VERSION ""

NS_ :

BS_:

BU_: MS6_Logger_CAN_Bus_1 GCM IZZE_RL IZZE_FL IZZE_RR IZZE_FR IMU SG_RIGHT SG_LEFT BRK_IR ABS PDM Wheel S350

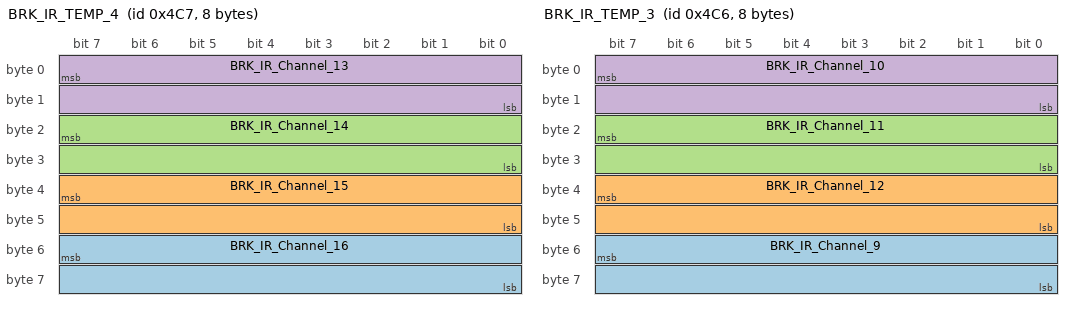
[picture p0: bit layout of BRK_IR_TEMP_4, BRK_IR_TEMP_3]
BO_ 1223 BRK_IR_TEMP_4: 8 Vector__XXX
 SG_ BRK_IR_Channel_16 : 55|16@0+ (0.1,-100) [0|65535] "C" Vector__XXX
 SG_ BRK_IR_Channel_15 : 39|16@0+ (0.1,-100) [0|65535] "C" Vector__XXX
 SG_ BRK_IR_Channel_14 : 23|16@0+ (0.1,-100) [0|65535] "C" Vector__XXX
 SG_ BRK_IR_Channel_13 : 7|16@0+ (0.1,-100) [0|65535] "C" Vector__XXX

BO_ 1222 BRK_IR_TEMP_3: 8 Vector__XXX
 SG_ BRK_IR_Channel_9 : 55|16@0+ (0.1,-100) [0|65535] "C" Vector__XXX
 SG_ BRK_IR_Channel_12 : 39|16@0+ (0.1,-100) [0|65535] "C" Vector__XXX
 SG_ BRK_IR_Channel_11 : 23|16@0+ (0.1,-100) [0|65535] "C" Vector__XXX
 SG_ BRK_IR_Channel_10 : 7|16@0+ (0.1,-100) [0|65535] "C" Vector__XXX

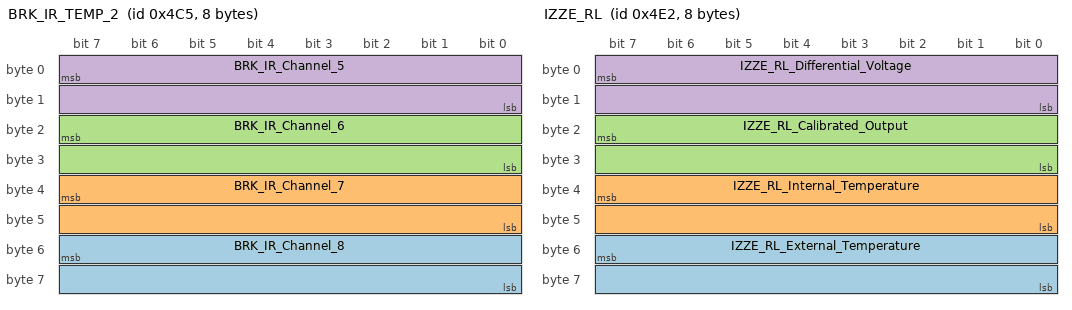
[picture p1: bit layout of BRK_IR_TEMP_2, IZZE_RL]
BO_ 1221 BRK_IR_TEMP_2: 8 Vector__XXX
 SG_ BRK_IR_Channel_8 : 55|16@0+ (0.1,-100) [0|65535] "C" Vector__XXX
 SG_ BRK_IR_Channel_7 : 39|16@0+ (0.1,-100) [0|65535] "C" Vector__XXX
 SG_ BRK_IR_Channel_6 : 23|16@0+ (0.1,-100) [0|65535] "C" Vector__XXX
 SG_ BRK_IR_Channel_5 : 7|16@0+ (0.1,-100) [0|65535] "C" Vector__XXX

BO_ 1552 GCM_Bosch: 8 GCM
 SG_ GCM_Upshift_Bosch : 1|1@1+ (1,0) [0|0] "" Vector__XXX
 SG_ GCM_Downshift_Bosch : 0|1@1+ (1,0) [0|0] "" Vector__XXX

BO_ 1250 IZZE_RL: 8 IZZE_RL
 SG_ IZZE_RL_External_Temperature : 55|16@0- (0.1,0) [0|0] "C" Vector__XXX
 SG_ IZZE_RL_Internal_Temperature : 39|16@0- (0.1,0) [0|0] "C" Vector__XXX
 SG_ IZZE_RL_Calibrated_Output : 23|16@0- (0.1,0) [0|0] "F" Vector__XXX
 SG_ IZZE_RL_Differential_Voltage : 7|16@0- (1,0) [0|0] "µV" Vector__XXX

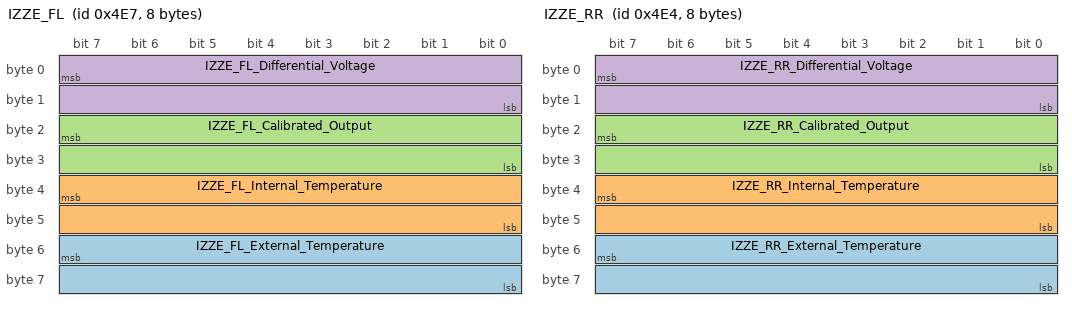
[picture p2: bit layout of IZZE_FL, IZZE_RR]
BO_ 1255 IZZE_FL: 8 IZZE_FL
 SG_ IZZE_FL_External_Temperature : 55|16@0- (0.1,0) [0|0] "C" Vector__XXX
 SG_ IZZE_FL_Internal_Temperature : 39|16@0- (0.1,0) [0|0] "C" Vector__XXX
 SG_ IZZE_FL_Calibrated_Output : 23|16@0- (0.1,0) [0|0] "F" Vector__XXX
 SG_ IZZE_FL_Differential_Voltage : 7|16@0- (1,0) [0|0] "µV" Vector__XXX

BO_ 1252 IZZE_RR: 8 IZZE_RR
 SG_ IZZE_RR_External_Temperature : 55|16@0- (0.1,0) [0|0] "C" Vector__XXX
 SG_ IZZE_RR_Internal_Temperature : 39|16@0- (0.1,0) [0|0] "C" Vector__XXX
 SG_ IZZE_RR_Calibrated_Output : 23|16@0- (0.1,0) [0|0] "F" Vector__XXX
 SG_ IZZE_RR_Differential_Voltage : 7|16@0- (1,0) [0|0] "µV" Vector__XXX

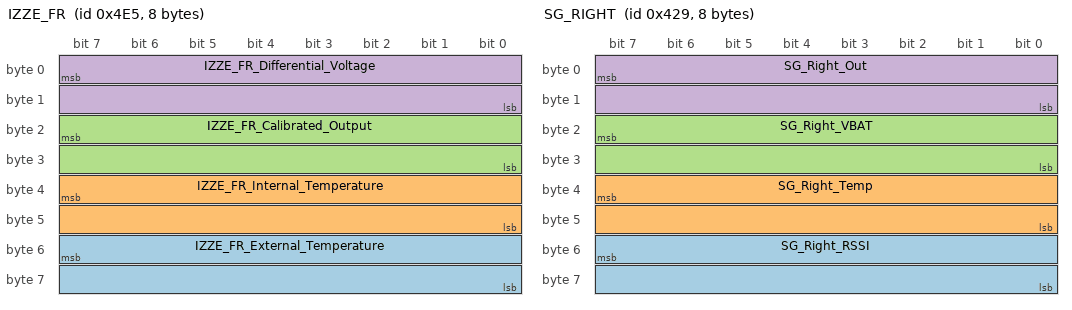
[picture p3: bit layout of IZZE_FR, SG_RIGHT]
BO_ 1253 IZZE_FR: 8 IZZE_FR
 SG_ IZZE_FR_External_Temperature : 55|16@0- (0.1,0) [0|0] "C" Vector__XXX
 SG_ IZZE_FR_Internal_Temperature : 39|16@0- (0.1,0) [0|0] "C" Vector__XXX
 SG_ IZZE_FR_Calibrated_Output : 23|16@0- (0.1,0) [0|0] "F" Vector__XXX
 SG_ IZZE_FR_Differential_Voltage : 7|16@0- (1,0) [0|0] "µV" Vector__XXX

BO_ 380 IMU2: 8 IMU
 SG_ IMU_Z_Accel : 32|16@1+ (0.0001274,-4.1746432) [0|0] "g" Vector__XXX

BO_ 1065 SG_RIGHT: 8 SG_RIGHT
 SG_ SG_Right_RSSI : 55|16@0- (1,0) [0|0] "dBm" Vector__XXX
 SG_ SG_Right_Temp : 39|16@0- (0.1,0) [0|0] "C" Vector__XXX
 SG_ SG_Right_VBAT : 23|16@0- (0.001,0) [0|0] "V" Vector__XXX
 SG_ SG_Right_Out : 7|16@0- (-1,0) [0|0] "uV" Vector__XXX

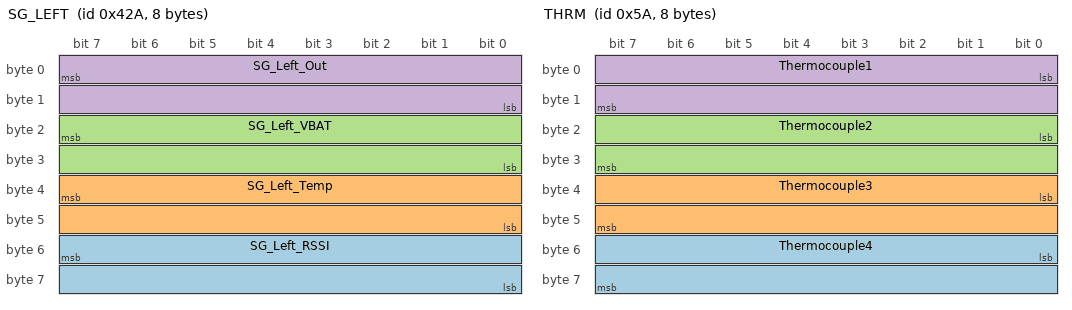
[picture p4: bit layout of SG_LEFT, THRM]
BO_ 1066 SG_LEFT: 8 SG_LEFT
 SG_ SG_Left_RSSI : 55|16@0- (1,0) [0|0] "dBm" Vector__XXX
 SG_ SG_Left_Temp : 39|16@0- (0.1,0) [0|0] "C" Vector__XXX
 SG_ SG_Left_VBAT : 23|16@0- (0.001,0) [0|0] "V" Vector__XXX
 SG_ SG_Left_Out : 7|16@0- (1,0) [0|0] "uV" Vector__XXX

BO_ 90 THRM: 8 Vector__XXX
 SG_ Thermocouple4 : 48|16@1- (0.25,0) [-32768|32767] "C" Vector__XXX
 SG_ Thermocouple3 : 32|16@1- (0.25,0) [-32768|32767] "C" Vector__XXX
 SG_ Thermocouple2 : 16|16@1- (0.25,0) [-32768|32767] "C" Vector__XXX
 SG_ Thermocouple1 : 0|16@1- (0.25,0) [-32768|32767] "C" Vector__XXX

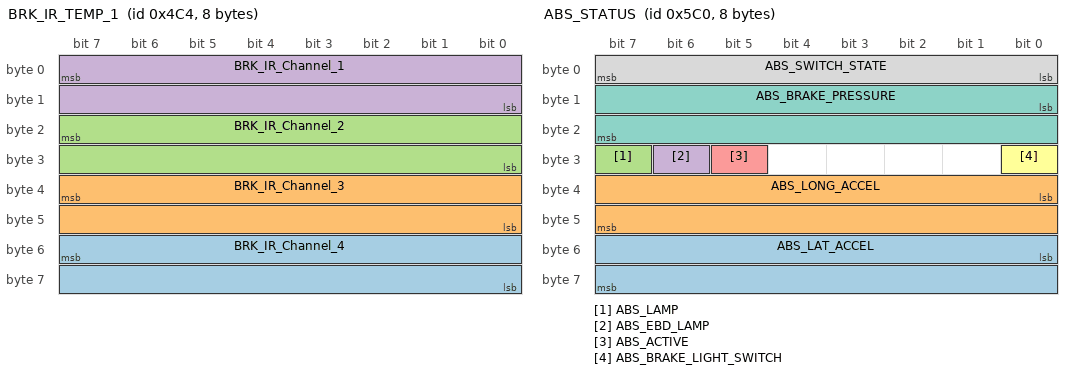
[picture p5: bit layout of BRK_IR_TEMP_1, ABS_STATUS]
BO_ 1220 BRK_IR_TEMP_1: 8 BRK_IR
 SG_ BRK_IR_Channel_4 : 55|16@0+ (0.1,-100) [0|65535] "C" Vector__XXX
 SG_ BRK_IR_Channel_3 : 39|16@0+ (0.1,-100) [0|65535] "C" Vector__XXX
 SG_ BRK_IR_Channel_2 : 23|16@0+ (0.1,-100) [0|65535] "C" Vector__XXX
 SG_ BRK_IR_Channel_1 : 7|16@0+ (0.1,-100) [0|65535] "C" Vector__XXX

BO_ 1472 ABS_STATUS: 8 ABS
 SG_ ABS_LAT_ACCEL : 48|16@1- (0.0001274,32768) [0|0] "g" Vector__XXX
 SG_ ABS_LONG_ACCEL : 32|16@1- (0.0001274,32768) [0|0] "g" Vector__XXX
 SG_ ABS_LAMP : 31|1@1+ (1,0) [0|0] "" Vector__XXX
 SG_ ABS_EBD_LAMP : 30|1@1+ (1,0) [0|0] "" Vector__XXX
 SG_ ABS_ACTIVE : 29|1@1+ (1,0) [0|0] "" Vector__XXX
 SG_ ABS_BRAKE_LIGHT_SWITCH : 24|1@1+ (1,0) [0|0] "" Vector__XXX
 SG_ ABS_BRAKE_PRESSURE : 8|16@1- (0.0153,0) [0|0] "bar" Vector__XXX
 SG_ ABS_SWITCH_STATE : 0|8@1+ (1,0) [0|0] "" Vector__XXX

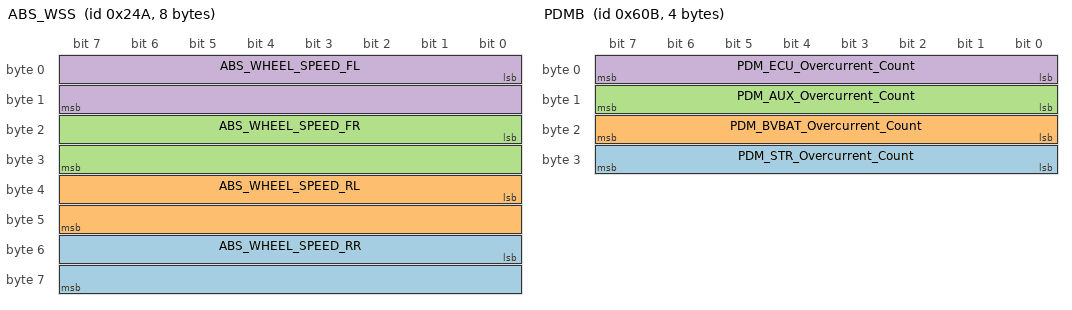
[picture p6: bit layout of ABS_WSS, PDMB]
BO_ 586 ABS_WSS: 8 ABS
 SG_ ABS_WHEEL_SPEED_RR : 48|16@1+ (0.015625,0) [0|0] "m/s" Vector__XXX
 SG_ ABS_WHEEL_SPEED_RL : 32|16@1+ (0.015625,0) [0|0] "m/s" Vector__XXX
 SG_ ABS_WHEEL_SPEED_FR : 16|16@1+ (0.015625,0) [0|0] "m/s" Vector__XXX
 SG_ ABS_WHEEL_SPEED_FL : 0|16@1+ (0.015625,0) [0|0] "m/s" Vector__XXX

BO_ 1027 BOSCH_LT2_3: 3 Vector__XXX
 SG_ LT2_Lambda_2 m0 : 8|16@1+ (0.001,0) [0|0] "L" Vector__XXX
 SG_ LT2_Row_Count M : 0|8@1+ (1,0) [0|0] "" Vector__XXX

BO_ 1122 BOSCH_LT2_2: 3 Vector__XXX
 SG_ LT2_Lambda_1 m0 : 8|16@1+ (0.001,0) [0|0] "L" Vector__XXX
 SG_ LT2_Row_Count M : 0|8@1+ (1,0) [0|0] "" Vector__XXX

BO_ 1121 BOSCH_LT2_1: 3 Vector__XXX
 SG_ LT2_Lambda_2 m0 : 8|16@1+ (0.001,0) [0|0] "L" Vector__XXX
 SG_ LT2_Row_Count M : 0|8@1+ (1,0) [0|0] "" Vector__XXX

BO_ 1120 BOSCH_LT2_0: 8 Vector__XXX
 SG_ LT2_Lambda_1 m0 : 8|16@1+ (0.001,0) [0|0] "L" Vector__XXX
 SG_ LT2_Row_Count M : 0|8@1+ (1,0) [0|0] "" Vector__XXX

BO_ 1547 PDMB: 4 PDM
 SG_ PDM_STR_Overcurrent_Count : 24|8@1+ (1,0) [0|0] "" Vector__XXX
 SG_ PDM_BVBAT_Overcurrent_Count : 16|8@1+ (1,0) [0|0] "" Vector__XXX
 SG_ PDM_AUX_Overcurrent_Count : 8|8@1+ (1,0) [0|0] "" Vector__XXX
 SG_ PDM_ECU_Overcurrent_Count : 0|8@1+ (1,0) [0|0] "" Vector__XXX

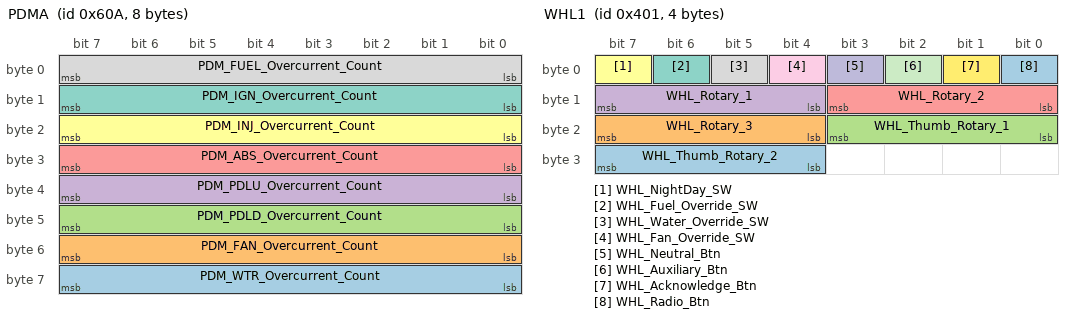
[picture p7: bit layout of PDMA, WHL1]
BO_ 1546 PDMA: 8 PDM
 SG_ PDM_WTR_Overcurrent_Count : 56|8@1+ (1,0) [0|0] "" Vector__XXX
 SG_ PDM_FAN_Overcurrent_Count : 48|8@1+ (1,0) [0|0] "" Vector__XXX
 SG_ PDM_PDLD_Overcurrent_Count : 40|8@1+ (1,0) [0|0] "" Vector__XXX
 SG_ PDM_PDLU_Overcurrent_Count : 32|8@1+ (1,0) [0|0] "" Vector__XXX
 SG_ PDM_ABS_Overcurrent_Count : 24|8@1+ (1,0) [0|0] "" Vector__XXX
 SG_ PDM_INJ_Overcurrent_Count : 16|8@1+ (1,0) [0|0] "" Vector__XXX
 SG_ PDM_IGN_Overcurrent_Count : 8|8@1+ (1,0) [0|0] "" Vector__XXX
 SG_ PDM_FUEL_Overcurrent_Count : 0|8@1+ (1,0) [0|0] "" Vector__XXX

BO_ 376 IMU1: 8 IMU
 SG_ IMU_X_Accel : 32|16@1+ (0.0001274,-4.1746432) [0|0] "g" Vector__XXX
 SG_ IMU_Roll_Rate : 0|16@1+ (0.005,-163.84) [0|0] "deg/s/s" Vector__XXX

BO_ 372 IMU0: 8 IMU
 SG_ IMU_Y_Accel : 32|16@1+ (0.0001274,-4.1746432) [0|0] "g" Vector__XXX
 SG_ IMU_Yaw_Rate : 0|16@1+ (0.005,-163.84) [0|0] "deg/s" Vector__XXX

BO_ 1025 WHL1: 4 Wheel
 SG_ WHL_Thumb_Rotary_2 : 28|4@1+ (1,0) [0|0] "" Vector__XXX
 SG_ WHL_Rotary_3 : 20|4@1+ (1,0) [0|0] "" Vector__XXX
 SG_ WHL_Thumb_Rotary_1 : 16|4@1+ (1,0) [0|0] "" Vector__XXX
 SG_ WHL_Rotary_1 : 12|4@1+ (1,0) [0|0] "" Vector__XXX
 SG_ WHL_Rotary_2 : 8|4@1+ (1,0) [0|0] "" Vector__XXX
 SG_ WHL_NightDay_SW : 7|1@1+ (1,0) [0|0] "" Vector__XXX
 SG_ WHL_Fuel_Override_SW : 6|1@1+ (1,0) [0|0] "" Vector__XXX
 SG_ WHL_Water_Override_SW : 5|1@1+ (1,0) [0|0] "" Vector__XXX
 SG_ WHL_Fan_Override_SW : 4|1@1+ (1,0) [0|0] "" Vector__XXX
 SG_ WHL_Neutral_Btn : 3|1@1+ (1,0) [0|0] "" Vector__XXX
 SG_ WHL_Auxiliary_Btn : 2|1@1+ (1,0) [0|0] "" Vector__XXX
 SG_ WHL_Acknowledge_Btn : 1|1@1+ (1,0) [0|0] "" Vector__XXX
 SG_ WHL_Radio_Btn : 0|1@1+ (1,0) [0|0] "" Vector__XXX

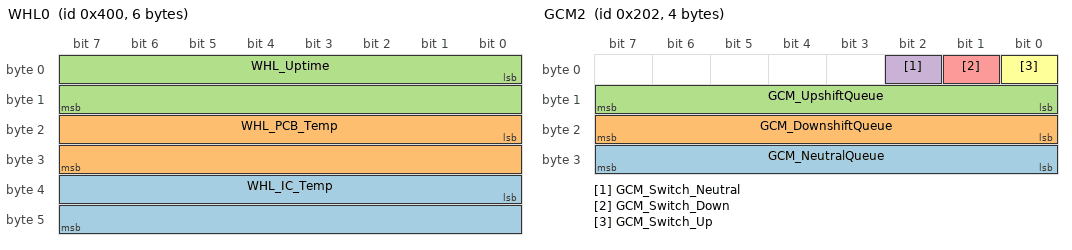
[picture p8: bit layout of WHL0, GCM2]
BO_ 1024 WHL0: 6 Wheel
 SG_ WHL_IC_Temp : 32|16@1- (0.005,0) [0|0] "C" Vector__XXX
 SG_ WHL_PCB_Temp : 16|16@1- (0.005,0) [0|0] "C" Vector__XXX
 SG_ WHL_Uptime : 0|16@1+ (1,0) [0|0] "s" Vector__XXX

BO_ 514 GCM2: 4 GCM
 SG_ GCM_NeutralQueue : 24|8@1+ (1,0) [0|0] "" Vector__XXX
 SG_ GCM_DownshiftQueue : 16|8@1+ (1,0) [0|0] "" Vector__XXX
 SG_ GCM_UpshiftQueue : 8|8@1+ (1,0) [0|0] "" Vector__XXX
 SG_ GCM_Switch_Neutral : 2|1@1+ (1,0) [0|0] "" Vector__XXX
 SG_ GCM_Switch_Down : 1|1@1+ (1,0) [0|0] "" Vector__XXX
 SG_ GCM_Switch_Up : 0|1@1+ (1,0) [0|0] "" Vector__XXX

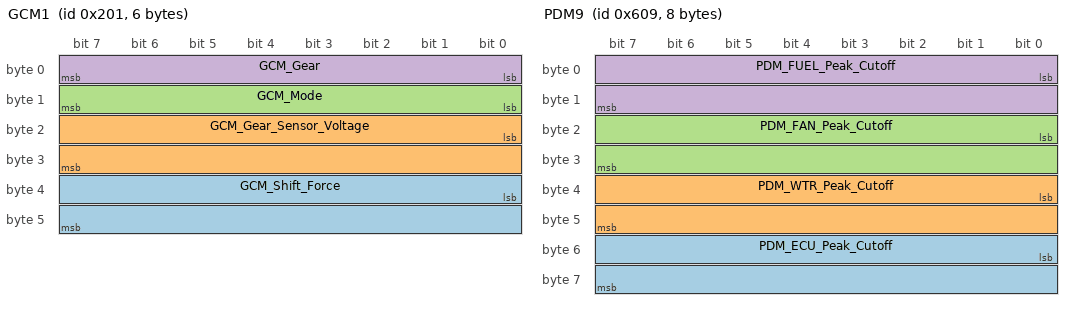
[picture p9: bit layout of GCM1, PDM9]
BO_ 513 GCM1: 6 GCM
 SG_ GCM_Shift_Force : 32|16@1- (0.01,0) [0|0] "N" Vector__XXX
 SG_ GCM_Gear_Sensor_Voltage : 16|16@1+ (0.0001,0) [0|0] "V" Vector__XXX
 SG_ GCM_Mode : 8|8@1+ (1,0) [0|0] "" Vector__XXX
 SG_ GCM_Gear : 0|8@1+ (1,0) [0|0] "" Vector__XXX

BO_ 15 ERR: 4 Vector__XXX
 SG_ ERR_Code : 16|16@1+ (1,0) [0|0] "" Vector__XXX
 SG_ ERR_Origin_Node : 0|16@1+ (1,0) [0|0] "" Vector__XXX

BO_ 1537 PDM1: 8 PDM
 SG_ PDM_FuelPrime : 63|1@1+ (1,0) [0|0] "" Vector__XXX
 SG_ PDM_OverTemp : 62|1@1+ (1,0) [0|0] "" Vector__XXX
 SG_ PDM_STR_SW : 55|1@1+ (1,0) [0|0] "" Vector__XXX
 SG_ PDM_ON_SW : 54|1@1+ (1,0) [0|0] "" Vector__XXX
 SG_ PDM_ACT_UP_SW : 53|1@1+ (1,0) [0|0] "" Vector__XXX
 SG_ PDM_ACT_DN_SW : 52|1@1+ (1,0) [0|0] "" Vector__XXX
 SG_ PDM_KILL_SW : 51|1@1+ (1,0) [0|0] "" Vector__XXX
 SG_ PDM_ABS_SW : 50|1@1+ (1,0) [0|0] "" Vector__XXX
 SG_ PDM_AUX1_SW : 49|1@1+ (1,0) [0|0] "" Vector__XXX
 SG_ PDM_AUX2_SW : 48|1@1+ (1,0) [0|0] "" Vector__XXX
 SG_ PDM_Total_Current : 32|16@1+ (0.01,0) [0|0] "A" Vector__XXX
 SG_ PDM_FUEL_Peak : 31|1@1+ (1,0) [0|0] "" Vector__XXX
 SG_ PDM_IGN_Peak : 30|1@1+ (1,0) [0|0] "" Vector__XXX
 SG_ PDM_INJ_Peak : 29|1@1+ (1,0) [0|0] "" Vector__XXX
 SG_ PDM_ABS_Peak : 28|1@1+ (1,0) [0|0] "" Vector__XXX
 SG_ PDM_PDLU_Peak : 27|1@1+ (1,0) [0|0] "" Vector__XXX
 SG_ PDM_PDLD_Peak : 26|1@1+ (1,0) [0|0] "" Vector__XXX
 SG_ PDM_FAN_Peak : 25|1@1+ (1,0) [0|0] "" Vector__XXX
 SG_ PDM_WTR_Peak : 24|1@1+ (1,0) [0|0] "" Vector__XXX
 SG_ PDM_ECU_Peak : 23|1@1+ (1,0) [0|0] "" Vector__XXX
 SG_ PDM_AUX_Peak : 22|1@1+ (1,0) [0|0] "" Vector__XXX
 SG_ PDM_BVBAT_Peak : 21|1@1+ (1,0) [0|0] "" Vector__XXX
 SG_ PDM_STR_Peak : 20|1@1+ (1,0) [0|0] "" Vector__XXX
 SG_ PDM_FUEL_Enabled : 15|1@1+ (1,0) [0|0] "" Vector__XXX
 SG_ PDM_IGN_Enabled : 14|1@1+ (1,0) [0|0] "" Vector__XXX
 SG_ PDM_INJ_Enabled : 13|1@1+ (1,0) [0|0] "" Vector__XXX
 SG_ PDM_ABS_Enabled : 12|1@1+ (1,0) [0|0] "" Vector__XXX
 SG_ PDM_PDLU_Enabled : 11|1@1+ (1,0) [0|0] "" Vector__XXX
 SG_ PDM_PDLD_Enabled : 10|1@1+ (1,0) [0|0] "" Vector__XXX
 SG_ PDM_FAN_Enabled : 9|1@1+ (1,0) [0|0] "" Vector__XXX
 SG_ PDM_WTR_Enabled : 8|1@1+ (1,0) [0|0] "" Vector__XXX
 SG_ PDM_ECU_Enabled : 7|1@1+ (1,0) [0|0] "" Vector__XXX
 SG_ PDM_AUX_Enabled : 6|1@1+ (1,0) [0|0] "" Vector__XXX
 SG_ PDM_BVBAT_Enabled : 5|1@1+ (1,0) [0|0] "" Vector__XXX
 SG_ PDM_STR_Enabled : 4|1@1+ (1,0) [0|0] "" Vector__XXX

BO_ 1545 PDM9: 8 PDM
 SG_ PDM_ECU_Peak_Cutoff : 48|16@1+ (0.0025,0) [0|0] "A" Vector__XXX
 SG_ PDM_WTR_Peak_Cutoff : 32|16@1+ (0.0025,0) [0|0] "A" Vector__XXX
 SG_ PDM_FAN_Peak_Cutoff : 16|16@1+ (0.0025,0) [0|0] "A" Vector__XXX
 SG_ PDM_FUEL_Peak_Cutoff : 0|16@1+ (0.0025,0) [0|0] "A" Vector__XXX

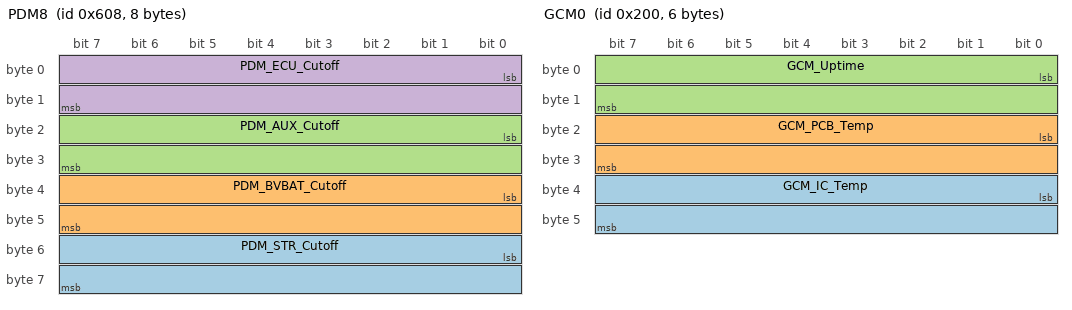
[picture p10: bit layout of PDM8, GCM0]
BO_ 1544 PDM8: 8 PDM
 SG_ PDM_STR_Cutoff : 48|16@1+ (0.0025,0) [0|0] "A" Vector__XXX
 SG_ PDM_BVBAT_Cutoff : 32|16@1+ (0.0025,0) [0|0] "A" Vector__XXX
 SG_ PDM_AUX_Cutoff : 16|16@1+ (0.0025,0) [0|0] "A" Vector__XXX
 SG_ PDM_ECU_Cutoff : 0|16@1+ (0.0025,0) [0|0] "A" Vector__XXX

BO_ 512 GCM0: 6 GCM
 SG_ GCM_IC_Temp : 32|16@1- (0.005,0) [0|0] "C" Vector__XXX
 SG_ GCM_PCB_Temp : 16|16@1- (0.005,0) [0|0] "C" Vector__XXX
 SG_ GCM_Uptime : 0|16@1+ (1,0) [0|0] "s" Vector__XXX

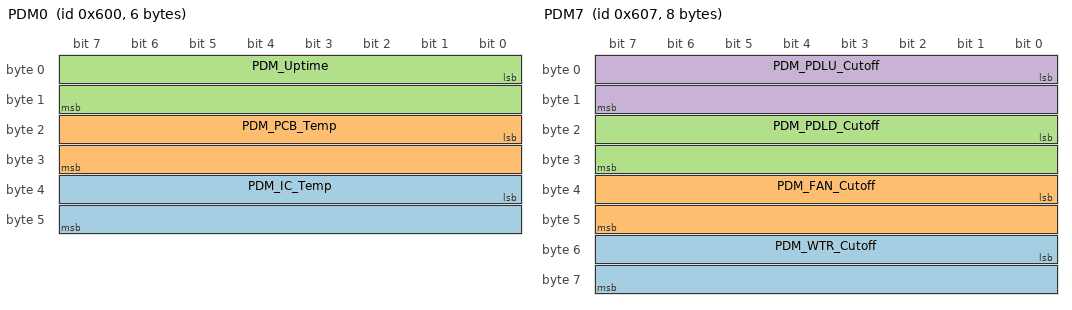
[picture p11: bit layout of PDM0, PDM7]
BO_ 1536 PDM0: 6 PDM
 SG_ PDM_IC_Temp : 32|16@1- (0.005,0) [0|0] "C" Vector__XXX
 SG_ PDM_PCB_Temp : 16|16@1- (0.005,0) [0|0] "C" Vector__XXX
 SG_ PDM_Uptime : 0|16@1+ (1,0) [0|0] "s" Vector__XXX

BO_ 1543 PDM7: 8 PDM
 SG_ PDM_WTR_Cutoff : 48|16@1+ (0.0025,0) [0|0] "A" Vector__XXX
 SG_ PDM_FAN_Cutoff : 32|16@1+ (0.0025,0) [0|0] "A" Vector__XXX
 SG_ PDM_PDLD_Cutoff : 16|16@1+ (0.0025,0) [0|0] "A" Vector__XXX
 SG_ PDM_PDLU_Cutoff : 0|16@1+ (0.0025,0) [0|0] "A" Vector__XXX

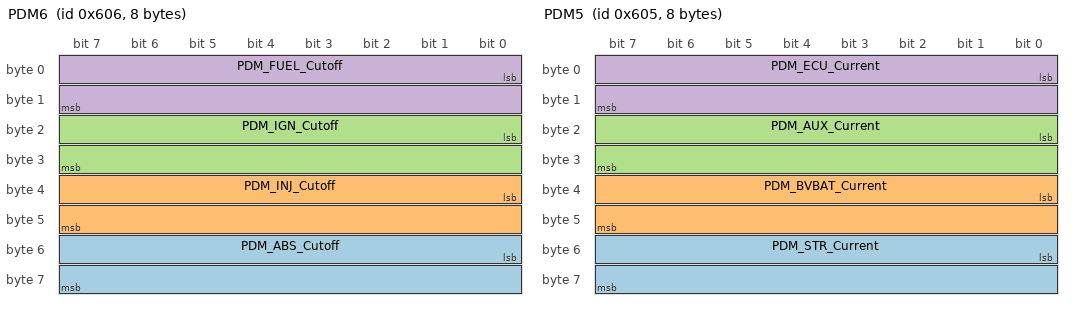
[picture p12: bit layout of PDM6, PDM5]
BO_ 1542 PDM6: 8 PDM
 SG_ PDM_ABS_Cutoff : 48|16@1+ (0.0025,0) [0|0] "A" Vector__XXX
 SG_ PDM_INJ_Cutoff : 32|16@1+ (0.0025,0) [0|0] "A" Vector__XXX
 SG_ PDM_IGN_Cutoff : 16|16@1+ (0.0025,0) [0|0] "A" Vector__XXX
 SG_ PDM_FUEL_Cutoff : 0|16@1+ (0.0025,0) [0|0] "A" Vector__XXX

BO_ 1541 PDM5: 8 PDM
 SG_ PDM_STR_Current : 48|16@1+ (0.01,0) [0|0] "A" Vector__XXX
 SG_ PDM_BVBAT_Current : 32|16@1+ (0.001,0) [0|0] "A" Vector__XXX
 SG_ PDM_AUX_Current : 16|16@1+ (0.001,0) [0|0] "A" Vector__XXX
 SG_ PDM_ECU_Current : 0|16@1+ (0.001,0) [0|0] "A" Vector__XXX

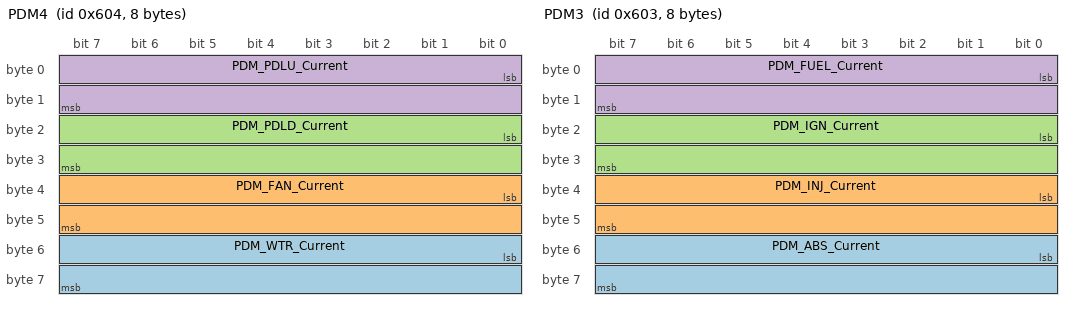
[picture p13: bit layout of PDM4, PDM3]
BO_ 1540 PDM4: 8 PDM
 SG_ PDM_WTR_Current : 48|16@1+ (0.001,0) [0|0] "A" Vector__XXX
 SG_ PDM_FAN_Current : 32|16@1+ (0.001,0) [0|0] "A" Vector__XXX
 SG_ PDM_PDLD_Current : 16|16@1+ (0.001,0) [0|0] "A" Vector__XXX
 SG_ PDM_PDLU_Current : 0|16@1+ (0.001,0) [0|0] "A" Vector__XXX

BO_ 1539 PDM3: 8 PDM
 SG_ PDM_ABS_Current : 48|16@1+ (0.001,0) [0|0] "A" Vector__XXX
 SG_ PDM_INJ_Current : 32|16@1+ (0.001,0) [0|0] "A" Vector__XXX
 SG_ PDM_IGN_Current : 16|16@1+ (0.001,0) [0|0] "A" Vector__XXX
 SG_ PDM_FUEL_Current : 0|16@1+ (0.001,0) [0|0] "A" Vector__XXX

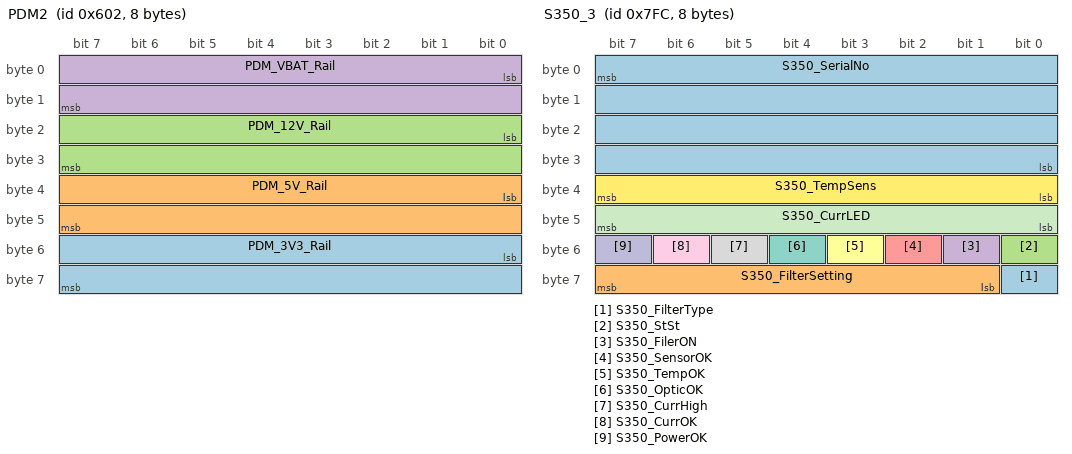
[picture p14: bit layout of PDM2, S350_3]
BO_ 1538 PDM2: 8 PDM
 SG_ PDM_3V3_Rail : 48|16@1+ (0.001,0) [0|0] "V" Vector__XXX
 SG_ PDM_5V_Rail : 32|16@1+ (0.001,0) [0|0] "V" Vector__XXX
 SG_ PDM_12V_Rail : 16|16@1+ (0.001,0) [0|0] "V" Vector__XXX
 SG_ PDM_VBAT_Rail : 0|16@1+ (0.001,0) [0|0] "V" Vector__XXX

BO_ 2044 S350_3: 8 S350
 SG_ S350_FilterType : 56|1@0+ (1,0) [0|1] ""  S350
 SG_ S350_FilterSetting : 63|7@0+ (1,0) [0|127] ""  S350
 SG_ S350_StSt : 48|1@0+ (1,0) [0|1] ""  S350
 SG_ S350_FilerON : 49|1@0+ (1,0) [0|1] ""  S350
 SG_ S350_SensorOK : 50|1@0+ (1,0) [0|1] ""  S350
 SG_ S350_TempOK : 51|1@0+ (1,0) [0|1] ""  S350
 SG_ S350_OpticOK : 52|1@0+ (1,0) [0|1] ""  S350
 SG_ S350_CurrHigh : 53|1@0+ (1,0) [0|1] ""  S350
 SG_ S350_CurrOK : 54|1@0+ (1,0) [0|1] ""  S350
 SG_ S350_PowerOK : 55|1@0+ (1,0) [0|1] ""  S350
 SG_ S350_CurrLED : 47|8@0+ (0.01,0) [0|2.55] "A"  S350
 SG_ S350_TempSens : 39|8@0- (1,0) [-128|127] "°C"  S350
 SG_ S350_SerialNo : 7|32@0+ (1,0) [0|4294970000] ""  S350

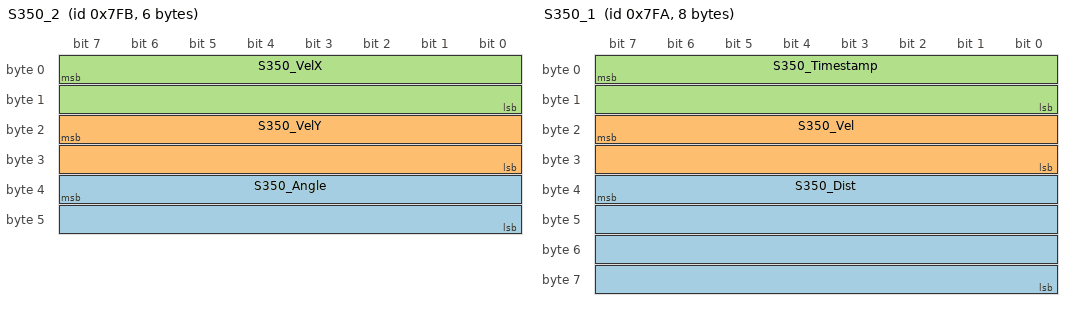
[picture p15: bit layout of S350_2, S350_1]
BO_ 2043 S350_2: 6 S350
 SG_ S350_Angle : 39|16@0- (0.01,0) [-45|45] "°"  S350
 SG_ S350_VelY : 23|16@0- (0.036,0) [-100|100] "km/h"  S350
 SG_ S350_VelX : 7|16@0+ (0.036,0) [0|400] "km/h"  S350

BO_ 2042 S350_1: 8 S350
 SG_ S350_Dist : 39|32@0+ (0.001,0) [0|4294970] "m"  S350
 SG_ S350_Vel : 23|16@0+ (0.036,0) [0|400] "km/h"  S350
 SG_ S350_Timestamp : 7|16@0+ (1,0) [0|65535] ""  S350

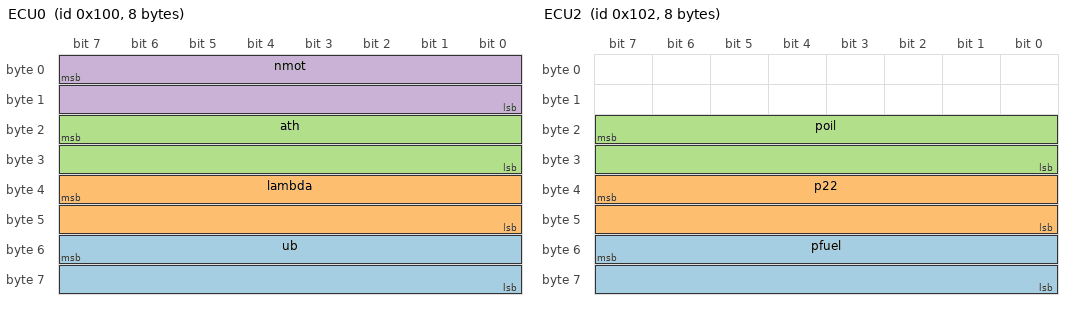
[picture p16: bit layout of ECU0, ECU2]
BO_ 256 ECU0: 8 MS6_Logger_CAN_Bus_1
 SG_ ub : 55|16@0- (0.01,0) [0|25.5] "V" Vector__XXX
 SG_ lambda : 39|16@0- (0.001,0) [0|5] "" Vector__XXX
 SG_ ath : 23|16@0- (0.1,0) [0|110] "%" Vector__XXX
 SG_ nmot : 7|16@0- (1,0) [0|20000] "rpm" Vector__XXX

BO_ 258 ECU2: 8 MS6_Logger_CAN_Bus_1
 SG_ pfuel : 55|16@0- (0.001,0) [0|10] "bar" Vector__XXX
 SG_ p22 : 39|16@0- (1,0) [0|5000] "mbar" Vector__XXX
 SG_ poil : 23|16@0- (0.001,0) [0|10] "bar" Vector__XXX

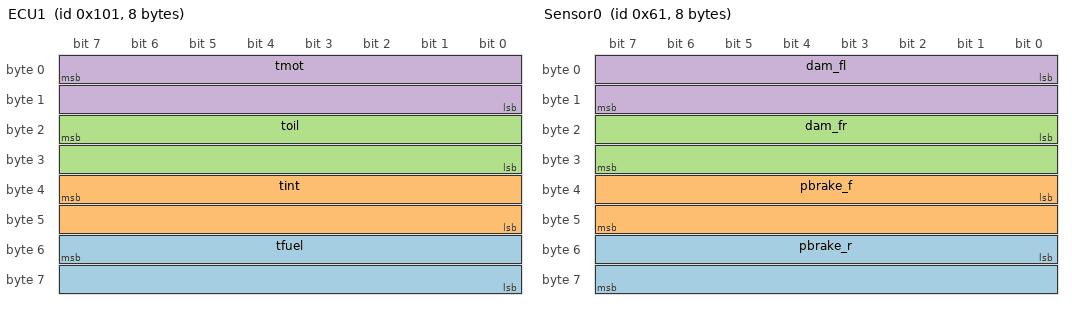
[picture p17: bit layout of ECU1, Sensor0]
BO_ 257 ECU1: 8 MS6_Logger_CAN_Bus_1
 SG_ tfuel : 55|16@0+ (0.1,0) [10|80] "°C" Vector__XXX
 SG_ tint : 39|16@0- (0.1,0) [10|60] "°C" Vector__XXX
 SG_ toil : 23|16@0- (0.1,0) [60|150] "°C" Vector__XXX
 SG_ tmot : 7|16@0- (0.1,0) [40|120] "°C" Vector__XXX

BO_ 259 ECU3: 8 MS6_Logger_CAN_Bus_1

BO_ 97 Sensor0: 8 MS6_Logger_CAN_Bus_1
 SG_ pbrake_r : 48|16@1+ (0.005,0) [0|150] "bar" Vector__XXX
 SG_ pbrake_f : 32|16@1+ (0.005,0) [0|150] "bar" Vector__XXX
 SG_ dam_fr : 16|16@1+ (0.015,0) [-400|400] "mm" Vector__XXX
 SG_ dam_fl : 0|16@1+ (0.015,0) [-400|400] "mm" Vector__XXX

CM_ BO_ 256 "RPM, Throttle Position, Lambda, VBAT";
CM_ SG_ 256 ub "battery voltage";
CM_ SG_ 256 lambda "Lambda actual value";
CM_ SG_ 256 ath "throttle position";
CM_ SG_ 256 nmot "engine speed";
CM_ BO_ 258 "Ambient Pressure, Oil Pressure, Manifold Pressure, Fuel Pressure";
CM_ SG_ 258 pfuel "fuel pressure";
CM_ SG_ 258 p22 "intake manifold pressure downstream throttle";
CM_ SG_ 258 poil "oil pressure";
CM_ BO_ 257 "Coolant Temp, Oil Temp, Manifold Temp, Fuel Temp";
CM_ SG_ 257 tfuel "fuel temperature";
CM_ SG_ 257 tint "intake air temperature";
CM_ SG_ 257 toil "oil temperature";
CM_ SG_ 257 tmot "engine temperature";
CM_ BO_ 259 "Wheel Speeds";
CM_ BO_ 97 "Front Damper Positions, Front Brake Pressure, Rear Brake Pressure";
CM_ SG_ 97 pbrake_r "brake pressure rear";
CM_ SG_ 97 pbrake_f "brake pressure front ";
CM_ SG_ 97 dam_fr "damper position front right";
CM_ SG_ 97 dam_fl "damper position front left";
VAL_ 2044 S350_FilterType 1 "FIR" 0 "MAVG" ;
VAL_ 2044 S350_FilerON 1 "ON" 0 "OFF" ;
